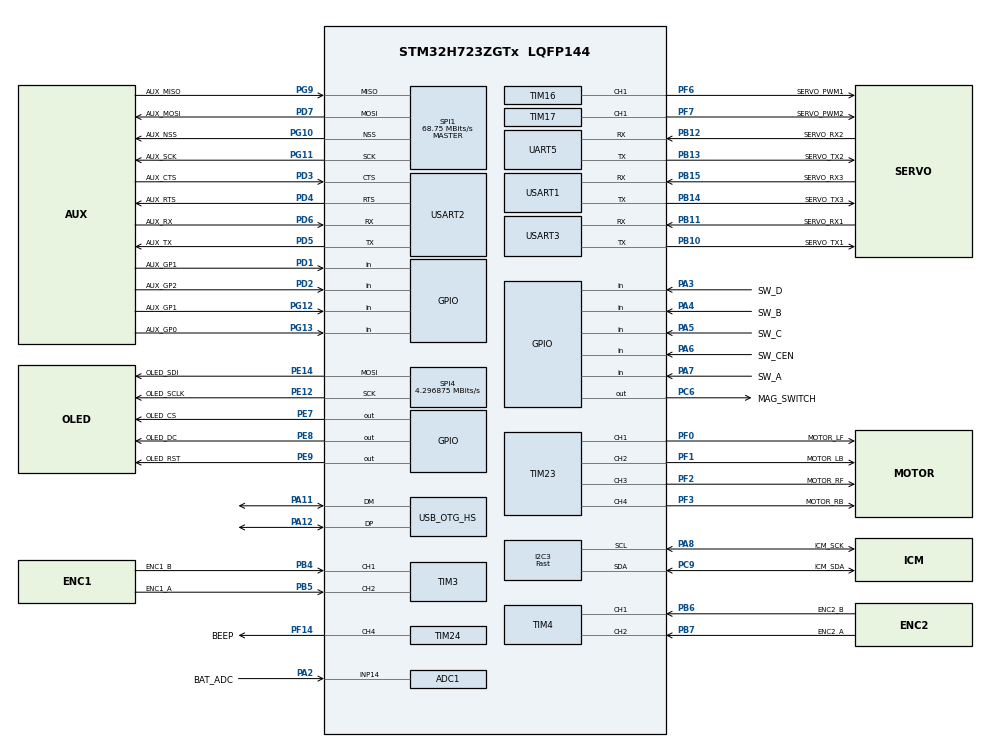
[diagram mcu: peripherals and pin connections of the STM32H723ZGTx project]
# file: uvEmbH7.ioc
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ADC1.Channel-0\#ChannelRegularConversion=ADC_CHANNEL_14
ADC1.ContinuousConvMode=ENABLE
ADC1.NbrOfConversion=1
ADC1.NbrOfConversionFlag=1
ADC1.OffsetNumber-0\#ChannelRegularConversion=ADC_OFFSET_NONE
ADC1.OffsetSignedSaturation-0\#ChannelRegularConversion=DISABLE
ADC1.Overrun=ADC_OVR_DATA_OVERWRITTEN
ADC1.Rank-0\#ChannelRegularConversion=1
ADC1.SamplingTime-0\#ChannelRegularConversion=ADC_SAMPLETIME_1CYCLE_5
ADC1.master=1
ADC3.Channel-0\#ChannelRegularConversion=ADC_CHANNEL_VBAT
ADC3.NbrOfConversionFlag=1
ADC3.OffsetNumber-0\#ChannelRegularConversion=ADC_OFFSET_NONE
ADC3.OffsetSign-0\#ChannelRegularConversion=ADC3_OFFSET_SIGN_NEGATIVE
ADC3.Rank-0\#ChannelRegularConversion=1
ADC3.SamplingTime-0\#ChannelRegularConversion=ADC3_SAMPLETIME_2CYCLES_5
CORTEX_M7.default_mode_Activation=1
FREERTOS.Tasks01=defaultTask,24,128,StartDefaultTask,Default,NULL,Dynamic,NULL,NULL
FREERTOS.configENABLE_FPU=1
FREERTOS.configTOTAL_HEAP_SIZE=32767
FREERTOS.configUSE_NEWLIB_REENTRANT=1
I2C3.Analog_Filter=I2C_ANALOGFILTER_DISABLE
I2C3.I2C_Speed_Mode=I2C_Fast
I2C3.Timing=0x00D056FC
Mcu.Family=STM32H7
Mcu.Name=STM32H723ZGTx
Mcu.Package=LQFP144
NVIC.OTG_HS_IRQn=true\:5\:0\:false\:false\:true\:true\:true\:false\:true
NVIC.PriorityGroup=NVIC_PRIORITYGROUP_4
NVIC.TIM6_DAC_IRQn=true\:15\:0\:false\:false\:true\:false\:false\:true\:true
NVIC.TimeBase=TIM6_DAC_IRQn
NVIC.TimeBaseIP=TIM6
PA11.Mode=Device_Only_FS
PA11.Signal=USB_OTG_HS_DM
PA12.Mode=Device_Only_FS
PA12.Signal=USB_OTG_HS_DP
PA13(JTMS/SWDIO).Mode=Serial_Wire
PA13(JTMS/SWDIO).Signal=DEBUG_JTMS-SWDIO
PA14(JTCK/SWCLK).Mode=Serial_Wire
PA14(JTCK/SWCLK).Signal=DEBUG_JTCK-SWCLK
PA2.GPIO_Label=BAT_ADC
PA2.Signal=ADCx_INP14
PA3.GPIO_Label=SW_D
PA3.GPIO_PuPd=GPIO_PULLUP
PA3.Signal=GPIO_Input
PA4.GPIO_Label=SW_B
PA4.GPIO_PuPd=GPIO_PULLUP
PA4.Signal=GPIO_Input
PA5.GPIO_Label=SW_C
PA5.GPIO_PuPd=GPIO_PULLUP
PA5.Signal=GPIO_Input
PA6.GPIO_Label=SW_CEN
PA6.GPIO_PuPd=GPIO_PULLUP
PA6.Signal=GPIO_Input
PA7.GPIO_Label=SW_A
PA7.GPIO_PuPd=GPIO_PULLUP
PA7.Signal=GPIO_Input
PA8.GPIO_Label=ICM_SCK
PA8.GPIO_Pu=GPIO_PULLUP
PA8.GPIO_Speed=GPIO_SPEED_FREQ_VERY_HIGH
PA8.Mode=I2C
PA8.Signal=I2C3_SCL
PB10.GPIO_Label=SERVO_TX1
PB10.GPIO_Speed=GPIO_SPEED_FREQ_VERY_HIGH
PB10.Mode=Asynchronous
PB10.Signal=USART3_TX
PB11.GPIO_Label=SERVO_RX1
PB11.GPIO_Speed=GPIO_SPEED_FREQ_VERY_HIGH
PB11.Mode=Asynchronous
PB11.Signal=USART3_RX
PB12.GPIO_Label=SERVO_RX2
PB12.GPIO_Speed=GPIO_SPEED_FREQ_VERY_HIGH
PB12.Mode=Asynchronous
PB12.Signal=UART5_RX
PB13.GPIO_Label=SERVO_TX2
PB13.GPIO_Speed=GPIO_SPEED_FREQ_VERY_HIGH
PB13.Mode=Asynchronous
PB13.Signal=UART5_TX
PB14.GPIO_Label=SERVO_TX3
PB14.GPIO_Speed=GPIO_SPEED_FREQ_VERY_HIGH
PB14.Mode=Asynchronous
PB14.Signal=USART1_TX
PB15.GPIO_Label=SERVO_RX3
PB15.GPIO_Speed=GPIO_SPEED_FREQ_VERY_HIGH
PB15.Mode=Asynchronous
PB15.Signal=USART1_RX
PB4(NJTRST).GPIO_Label=ENC1_B
PB4(NJTRST).GPIO_Speed=GPIO_SPEED_FREQ_VERY_HIGH
PB4(NJTRST).Signal=S_TIM3_CH1
PB5.GPIO_Label=ENC1_A
PB5.GPIO_Speed=GPIO_SPEED_FREQ_VERY_HIGH
PB5.Signal=S_TIM3_CH2
PB6.GPIO_Label=ENC2_B
PB6.GPIO_Speed=GPIO_SPEED_FREQ_VERY_HIGH
PB6.Signal=S_TIM4_CH1
PB7.GPIO_Label=ENC2_A
PB7.GPIO_Speed=GPIO_SPEED_FREQ_VERY_HIGH
PB7.Signal=S_TIM4_CH2
PC14-OSC32_IN.Mode=LSE-External-Oscillator
PC14-OSC32_IN.Signal=RCC_OSC32_IN
PC15-OSC32_OUT.Mode=LSE-External-Oscillator
PC15-OSC32_OUT.Signal=RCC_OSC32_OUT
PC6.GPIO_Label=MAG_SWITCH
PC6.GPIO_PuPd=GPIO_PULLDOWN
PC6.GPIO_Speed=GPIO_SPEED_FREQ_VERY_HIGH
PC6.Signal=GPIO_Output
PC9.GPIO_Label=ICM_SDA
PC9.GPIO_Pu=GPIO_PULLUP
PC9.GPIO_Speed=GPIO_SPEED_FREQ_VERY_HIGH
PC9.Mode=I2C
PC9.Signal=I2C3_SDA
PD1.GPIO_Label=AUX_GP1
PD1.GPIO_PuPd=GPIO_PULLUP
PD1.Signal=GPIO_Input
PD2.GPIO_Label=AUX_GP2
PD2.GPIO_PuPd=GPIO_PULLUP
PD2.Signal=GPIO_Input
PD3.GPIO_Label=AUX_CTS
PD3.GPIO_Speed=GPIO_SPEED_FREQ_VERY_HIGH
PD3.Mode=CTS_RTS
PD3.Signal=USART2_CTS
PD4.GPIO_Label=AUX_RTS
PD4.GPIO_Speed=GPIO_SPEED_FREQ_VERY_HIGH
PD4.Mode=CTS_RTS
PD4.Signal=USART2_RTS
PD5.GPIO_Label=AUX_TX
PD5.GPIO_Speed=GPIO_SPEED_FREQ_VERY_HIGH
PD5.Mode=Asynchronous
PD5.Signal=USART2_TX
PD6.GPIO_Label=AUX_RX
PD6.GPIO_Speed=GPIO_SPEED_FREQ_VERY_HIGH
PD6.Mode=Asynchronous
PD6.Signal=USART2_RX
PD7.GPIO_Label=AUX_MOSI
PD7.GPIO_Speed=GPIO_SPEED_FREQ_VERY_HIGH
PD7.Mode=Full_Duplex_Master
PD7.Signal=SPI1_MOSI
PE12.GPIO_Label=OLED_SCLK
PE12.GPIO_Speed=GPIO_SPEED_FREQ_VERY_HIGH
PE12.Mode=TX_Only_Simplex_Unidirect_Master
PE12.Signal=SPI4_SCK
PE14.GPIO_Label=OLED_SDI
PE14.GPIO_Speed=GPIO_SPEED_FREQ_VERY_HIGH
PE14.Mode=TX_Only_Simplex_Unidirect_Master
PE14.Signal=SPI4_MOSI
PE7.GPIO_Label=OLED_CS
PE7.GPIO_PuPd=GPIO_PULLUP
PE7.GPIO_Speed=GPIO_SPEED_FREQ_VERY_HIGH
PE7.PinState=GPIO_PIN_SET
PE7.Signal=GPIO_Output
PE8.GPIO_Label=OLED_DC
PE8.GPIO_PuPd=GPIO_PULLUP
PE8.GPIO_Speed=GPIO_SPEED_FREQ_VERY_HIGH
PE8.PinState=GPIO_PIN_SET
PE8.Signal=GPIO_Output
PE9.GPIO_Label=OLED_RST
PE9.GPIO_PuPd=GPIO_PULLUP
PE9.GPIO_Speed=GPIO_SPEED_FREQ_VERY_HIGH
PE9.PinState=GPIO_PIN_SET
PE9.Signal=GPIO_Output
PF0.GPIO_Label=MOTOR_LF
PF0.GPIO_PuPd=GPIO_PULLDOWN
PF0.GPIO_Speed=GPIO_SPEED_FREQ_VERY_HIGH
PF0.Mode=PWM Generation1 CH1
PF0.Signal=TIM23_CH1
PF1.GPIO_Label=MOTOR_LB
PF1.GPIO_PuPd=GPIO_PULLDOWN
PF1.GPIO_Speed=GPIO_SPEED_FREQ_VERY_HIGH
PF1.Signal=S_TIM23_CH2
PF14.GPIO_Label=BEEP
PF14.GPIO_PuPd=GPIO_NOPULL
PF14.GPIO_Speed=GPIO_SPEED_FREQ_VERY_HIGH
PF14.Signal=S_TIM24_CH4
PF2.GPIO_Label=MOTOR_RF
PF2.GPIO_PuPd=GPIO_PULLDOWN
PF2.GPIO_Speed=GPIO_SPEED_FREQ_VERY_HIGH
PF2.Signal=S_TIM23_CH3
PF3.GPIO_Label=MOTOR_RB
PF3.GPIO_PuPd=GPIO_PULLDOWN
PF3.GPIO_Speed=GPIO_SPEED_FREQ_VERY_HIGH
PF3.Signal=S_TIM23_CH4
PF6.GPIO_Label=SERVO_PWM1
PF6.GPIO_PuPd=GPIO_PULLDOWN
PF6.GPIO_Speed=GPIO_SPEED_FREQ_VERY_HIGH
PF6.Signal=S_TIM16_CH1
PF7.GPIO_Label=SERVO_PWM2
PF7.GPIO_PuPd=GPIO_PULLDOWN
PF7.GPIO_Speed=GPIO_SPEED_FREQ_VERY_HIGH
PF7.Signal=S_TIM17_CH1
PG10.GPIO_Label=AUX_NSS
PG10.GPIO_Speed=GPIO_SPEED_FREQ_VERY_HIGH
PG10.Mode=NSS_Signal_Hard_Output
PG10.Signal=SPI1_NSS
PG11.GPIO_Label=AUX_SCK
PG11.GPIO_Speed=GPIO_SPEED_FREQ_VERY_HIGH
PG11.Mode=Full_Duplex_Master
PG11.Signal=SPI1_SCK
PG12.GPIO_Label=AUX_GP1
PG12.GPIO_PuPd=GPIO_PULLUP
PG12.Signal=GPIO_Input
PG13.GPIO_Label=AUX_GP0
PG13.GPIO_PuPd=GPIO_PULLUP
PG13.Signal=GPIO_Input
PG9.GPIO_Label=AUX_MISO
PG9.GPIO_Speed=GPIO_SPEED_FREQ_VERY_HIGH
PG9.Mode=Full_Duplex_Master
PG9.Signal=SPI1_MISO
PH0-OSC_IN.Mode=HSE-External-Oscillator
PH0-OSC_IN.Signal=RCC_OSC_IN
PH1-OSC_OUT.Mode=HSE-External-Oscillator
PH1-OSC_OUT.Signal=RCC_OSC_OUT
ProjectManager.HeapSize=0x2000
ProjectManager.StackSize=0x4000
ProjectManager.TargetToolchain=STM32CubeIDE
RCC.ADCFreq_Value=96000000
RCC.APB1Freq_Value=137500000
RCC.APB2Freq_Value=137500000
RCC.APB3Freq_Value=137500000
RCC.APB4Freq_Value=137500000
RCC.CortexFreq_Value=550000000
RCC.D1PPRE=RCC_APB3_DIV2
RCC.D2PPRE1=RCC_APB1_DIV2
RCC.D2PPRE2=RCC_APB2_DIV2
RCC.D3PPRE=RCC_APB4_DIV2
RCC.DIVM1=1
RCC.DIVM2=1
RCC.DIVM3=1
RCC.DIVN1=68
RCC.DIVN2=24
RCC.DIVN3=24
RCC.DIVP1=1
RCC.DIVQ1=4
RCC.DIVQ3=4
RCC.HCLKFreq_Value=275000000
RCC.HPRE=RCC_HCLK_DIV2
RCC.HSE_VALUE=8000000
RCC.PLL2FRACN=0
RCC.PLL3FRACN=0
RCC.PLLFRACN=6144
RCC.SYSCLKFreq_VALUE=550000000
RCC.SYSCLKSource=RCC_SYSCLKSOURCE_PLLCLK
RCC.USBCLockSelection=RCC_USBCLKSOURCE_PLL3
RCC.USBFreq_Value=48000000
SH.ADCx_INP14.0=ADC1_INP14,IN14-Single-Ended
SH.S_TIM16_CH1.0=TIM16_CH1,PWM Generation1 CH1
SH.S_TIM17_CH1.0=TIM17_CH1,PWM Generation1 CH1
SH.S_TIM23_CH2.0=TIM23_CH2,PWM Generation2 CH2
SH.S_TIM23_CH3.0=TIM23_CH3,PWM Generation3 CH3
SH.S_TIM23_CH4.0=TIM23_CH4,PWM Generation4 CH4
SH.S_TIM24_CH4.0=TIM24_CH4,PWM Generation4 CH4
SH.S_TIM3_CH1.0=TIM3_CH1,Encoder_Interface
SH.S_TIM3_CH2.0=TIM3_CH2,Encoder_Interface
SH.S_TIM4_CH1.0=TIM4_CH1,Encoder_Interface
SH.S_TIM4_CH2.0=TIM4_CH2,Encoder_Interface
SPI1.CalculateBaudRate=68.75 MBits/s
SPI1.Direction=SPI_DIRECTION_2LINES
SPI1.Mode=SPI_MODE_MASTER
SPI1.VirtualNSS=VM_NSSHARD
SPI1.VirtualType=VM_MASTER
SPI4.BaudRatePrescaler=SPI_BAUDRATEPRESCALER_32
SPI4.CalculateBaudRate=4.296875 MBits/s
SPI4.DataSize=SPI_DATASIZE_8BIT
SPI4.Direction=SPI_DIRECTION_2LINES_TXONLY
SPI4.Mode=SPI_MODE_MASTER
SPI4.VirtualType=VM_MASTER
STMicroelectronics.X-CUBE-MEMS1.11.0.0.SensorsJjSTM32IiMotionFXIiLibraryJjCore=true
TIM16.Channel=TIM_CHANNEL_1
TIM17.Channel=TIM_CHANNEL_1
TIM23.Channel-PWM\ Generation1\ CH1=TIM_CHANNEL_1
TIM23.Channel-PWM\ Generation2\ CH2=TIM_CHANNEL_2
TIM23.Channel-PWM\ Generation3\ CH3=TIM_CHANNEL_3
TIM23.Channel-PWM\ Generation4\ CH4=TIM_CHANNEL_4
TIM23.OCMode_PWM-PWM\ Generation1\ CH1=TIM_OCMODE_PWM2
TIM23.OCMode_PWM-PWM\ Generation2\ CH2=TIM_OCMODE_PWM2
TIM23.OCMode_PWM-PWM\ Generation3\ CH3=TIM_OCMODE_PWM2
TIM23.OCMode_PWM-PWM\ Generation4\ CH4=TIM_OCMODE_PWM2
TIM24.AutoReloadPreload=TIM_AUTORELOAD_PRELOAD_DISABLE
TIM24.Channel-PWM\ Generation4\ CH4=TIM_CHANNEL_4
TIM24.OC4Preload_PWM=DISABLE
TIM24.OCFastMode_PWM-PWM\ Generation4\ CH4=TIM_OCFAST_ENABLE
TIM24.OCMode_PWM-PWM\ Generation4\ CH4=TIM_OCMODE_PWM2
USART1.VirtualMode-Asynchronous=VM_ASYNC
USART2.VirtualMode-Asynchronous=VM_ASYNC
USART3.VirtualMode-Asynchronous=VM_ASYNC
USB_OTG_HS.VirtualMode-Device_Only_FS=Device_Only_FS
VP_ADC3_TempSens_Input.Mode=IN-TempSens
VP_ADC3_Vbat_Input.Mode=IN-Vbat
VP_ADC3_Vref_Input.Mode=IN-Vrefint
VP_CORDIC_VS_CORDIC.Mode=CORDIC_Activate
VP_CRC_VS_CRC.Mode=CRC_Activate
VP_FREERTOS_VS_CMSIS_V2.Mode=CMSIS_V2
VP_MEMORYMAP_VS_MEMORYMAP.Mode=CurAppReg
VP_RNG_VS_RNG.Mode=RNG_Activate
VP_STMicroelectronics.X-CUBE-MEMS1_VS_SensorsJjSTM32IiMotionFXIiLibrary_2.8.0_11.0.0.Mode=SensorsJjSTM32IiMotionFXIiLibrary
VP_SYS_VS_tim6.Mode=TIM6
VP_TIM16_VS_ClockSourceINT.Mode=Enable_Timer
VP_TIM17_VS_ClockSourceINT.Mode=Enable_Timer
VP_TIM23_VS_ClockSourceINT.Mode=Internal
VP_TIM24_VS_ClockSourceINT.Mode=Internal
board=custom

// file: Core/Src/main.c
/* USER CODE BEGIN Header */
/**
  ******************************************************************************
  * @file           : main.c
  * @brief          : Main program body
  ******************************************************************************
  * @attention
  *
  * Copyright (c) 2024 STMicroelectronics.
  * All rights reserved.
  *
  * This software is licensed under terms that can be found in the LICENSE file
  * in the root directory of this software component.
  * If no LICENSE file comes with this software, it is provided AS-IS.
  *
  ******************************************************************************
  */
/* USER CODE END Header */
#include "main.h"
#include "cmsis_os.h"
#include "adc.h"
#include "cordic.h"
#include "crc.h"
#include "i2c.h"
#include "memorymap.h"
#include "rng.h"
#include "spi.h"
#include "tim.h"
#include "usart.h"
#include "usb_otg.h"
#include "gpio.h"

/* USER CODE BEGIN Includes */
#include "apps.h"
/* USER CODE END Includes */

void SystemClock_Config(void);
void PeriphCommonClock_Config(void);
static void MPU_Config(void);
void MX_FREERTOS_Init(void);

int main(void)
{

  /* MPU Configuration--------------------------------------------------------*/
  MPU_Config();

  /* MCU Configuration--------------------------------------------------------*/

  /* Reset of all peripherals, Initializes the Flash interface and the Systick. */
  HAL_Init();

  /* Configure the system clock */
  SystemClock_Config();

  /* Configure the peripherals common clocks */
  PeriphCommonClock_Config();

  /* Initialize all configured peripherals */
  MX_GPIO_Init();
  MX_CORDIC_Init();
  MX_CRC_Init();
  MX_RNG_Init();
  MX_ADC3_Init();
  MX_I2C3_Init();
  MX_SPI4_Init();
  MX_TIM3_Init();
  MX_TIM4_Init();
  MX_TIM16_Init();
  MX_TIM17_Init();
  MX_TIM23_Init();
  MX_UART5_Init();
  MX_USART1_UART_Init();
  MX_USART3_UART_Init();
  MX_ADC1_Init();
  MX_SPI1_Init();
  MX_USART2_UART_Init();
  MX_TIM24_Init();
  MX_USB_OTG_HS_PCD_Init();

  /* Init scheduler */
  osKernelInitialize();

  /* Call init function for freertos objects (in cmsis_os2.c) */
  MX_FREERTOS_Init();

  /* Start scheduler */
  osKernelStart();

  /* We should never get here as control is now taken by the scheduler */

  /* Infinite loop */
  /* USER CODE BEGIN WHILE */
  // board_init();
  while (1)
  {
    /* USER CODE END WHILE */

    /* USER CODE BEGIN 3 */
//	if (HAL_GPIO_ReadPin(SW_A_GPIO_Port, SW_A_Pin) == 0)
//	{
//		_set_pwm_freq(NOTE_C6);
//		emag_enable();
//	}
//	else
//	{
//		_set_pwm_freq(0);
//		emag_disable();
//	}
//	HAL_Delay(200);
  }
  /* USER CODE END 3 */
}

void SystemClock_Config(void)
{
  RCC_OscInitTypeDef RCC_OscInitStruct = {0};
  RCC_ClkInitTypeDef RCC_ClkInitStruct = {0};

  /** Supply configuration update enable
  */
  HAL_PWREx_ConfigSupply(PWR_LDO_SUPPLY);

  /** Configure the main internal regulator output voltage
  */
  __HAL_PWR_VOLTAGESCALING_CONFIG(PWR_REGULATOR_VOLTAGE_SCALE0);

  while(!__HAL_PWR_GET_FLAG(PWR_FLAG_VOSRDY)) {}

  /** Initializes the RCC Oscillators according to the specified parameters
  * in the RCC_OscInitTypeDef structure.
  */
  RCC_OscInitStruct.OscillatorType = RCC_OSCILLATORTYPE_HSI48|RCC_OSCILLATORTYPE_HSE;
  RCC_OscInitStruct.HSEState = RCC_HSE_ON;
  RCC_OscInitStruct.HSI48State = RCC_HSI48_ON;
  RCC_OscInitStruct.PLL.PLLState = RCC_PLL_ON;
  RCC_OscInitStruct.PLL.PLLSource = RCC_PLLSOURCE_HSE;
  RCC_OscInitStruct.PLL.PLLM = 1;
  RCC_OscInitStruct.PLL.PLLN = 68;
  RCC_OscInitStruct.PLL.PLLP = 1;
  RCC_OscInitStruct.PLL.PLLQ = 4;
  RCC_OscInitStruct.PLL.PLLR = 2;
  RCC_OscInitStruct.PLL.PLLRGE = RCC_PLL1VCIRANGE_3;
  RCC_OscInitStruct.PLL.PLLVCOSEL = RCC_PLL1VCOWIDE;
  RCC_OscInitStruct.PLL.PLLFRACN = 6144;
  if (HAL_RCC_OscConfig(&RCC_OscInitStruct) != HAL_OK)
  {
    Error_Handler();
  }

  /** Initializes the CPU, AHB and APB buses clocks
  */
  RCC_ClkInitStruct.ClockType = RCC_CLOCKTYPE_HCLK|RCC_CLOCKTYPE_SYSCLK
                              |RCC_CLOCKTYPE_PCLK1|RCC_CLOCKTYPE_PCLK2
                              |RCC_CLOCKTYPE_D3PCLK1|RCC_CLOCKTYPE_D1PCLK1;
  RCC_ClkInitStruct.SYSCLKSource = RCC_SYSCLKSOURCE_PLLCLK;
  RCC_ClkInitStruct.SYSCLKDivider = RCC_SYSCLK_DIV1;
  RCC_ClkInitStruct.AHBCLKDivider = RCC_HCLK_DIV2;
  RCC_ClkInitStruct.APB3CLKDivider = RCC_APB3_DIV2;
  RCC_ClkInitStruct.APB1CLKDivider = RCC_APB1_DIV2;
  RCC_ClkInitStruct.APB2CLKDivider = RCC_APB2_DIV2;
  RCC_ClkInitStruct.APB4CLKDivider = RCC_APB4_DIV2;

  if (HAL_RCC_ClockConfig(&RCC_ClkInitStruct, FLASH_LATENCY_3) != HAL_OK)
  {
    Error_Handler();
  }
}

void PeriphCommonClock_Config(void)
{
  RCC_PeriphCLKInitTypeDef PeriphClkInitStruct = {0};

  /** Initializes the peripherals clock
  */
  PeriphClkInitStruct.PeriphClockSelection = RCC_PERIPHCLK_ADC;
  PeriphClkInitStruct.PLL2.PLL2M = 1;
  PeriphClkInitStruct.PLL2.PLL2N = 24;
  PeriphClkInitStruct.PLL2.PLL2P = 2;
  PeriphClkInitStruct.PLL2.PLL2Q = 2;
  PeriphClkInitStruct.PLL2.PLL2R = 2;
  PeriphClkInitStruct.PLL2.PLL2RGE = RCC_PLL2VCIRANGE_3;
  PeriphClkInitStruct.PLL2.PLL2VCOSEL = RCC_PLL2VCOWIDE;
  PeriphClkInitStruct.PLL2.PLL2FRACN = 0;
  PeriphClkInitStruct.AdcClockSelection = RCC_ADCCLKSOURCE_PLL2;
  if (HAL_RCCEx_PeriphCLKConfig(&PeriphClkInitStruct) != HAL_OK)
  {
    Error_Handler();
  }
}

 /* MPU Configuration */

void MPU_Config(void)
{
  MPU_Region_InitTypeDef MPU_InitStruct = {0};

  /* Disables the MPU */
  HAL_MPU_Disable();

  /** Initializes and configures the Region and the memory to be protected
  */
  MPU_InitStruct.Enable = MPU_REGION_ENABLE;
  MPU_InitStruct.Number = MPU_REGION_NUMBER0;
  MPU_InitStruct.BaseAddress = 0x0;
  MPU_InitStruct.Size = MPU_REGION_SIZE_4GB;
  MPU_InitStruct.SubRegionDisable = 0x87;
  MPU_InitStruct.TypeExtField = MPU_TEX_LEVEL0;
  MPU_InitStruct.AccessPermission = MPU_REGION_NO_ACCESS;
  MPU_InitStruct.DisableExec = MPU_INSTRUCTION_ACCESS_DISABLE;
  MPU_InitStruct.IsShareable = MPU_ACCESS_SHAREABLE;
  MPU_InitStruct.IsCacheable = MPU_ACCESS_NOT_CACHEABLE;
  MPU_InitStruct.IsBufferable = MPU_ACCESS_NOT_BUFFERABLE;

  HAL_MPU_ConfigRegion(&MPU_InitStruct);
  /* Enables the MPU */
  HAL_MPU_Enable(MPU_PRIVILEGED_DEFAULT);

}

void HAL_TIM_PeriodElapsedCallback(TIM_HandleTypeDef *htim)
{
  if (htim->Instance == TIM6) {
    HAL_IncTick();
  }
}

void Error_Handler(void)
{
  __disable_irq();
  while (1)
  {
  }
}

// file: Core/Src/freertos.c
/* USER CODE BEGIN Header */
/**
  ******************************************************************************
  * File Name          : freertos.c
  * Description        : Code for freertos applications
  ******************************************************************************
  * @attention
  *
  * Copyright (c) 2024 STMicroelectronics.
  * All rights reserved.
  *
  * This software is licensed under terms that can be found in the LICENSE file
  * in the root directory of this software component.
  * If no LICENSE file comes with this software, it is provided AS-IS.
  *
  ******************************************************************************
  */
/* USER CODE END Header */

#include "FreeRTOS.h"
#include "task.h"
#include "main.h"
#include "cmsis_os.h"

/* USER CODE BEGIN Includes */
#include "apps.h"
/* USER CODE END Includes */

/* Definitions for defaultTask */
osThreadId_t defaultTaskHandle;
const osThreadAttr_t defaultTask_attributes = {
  .name = "defaultTask",
  .stack_size = 128 * 4,
  .priority = (osPriority_t) osPriorityNormal,
};

void StartDefaultTask(void *argument);

void MX_FREERTOS_Init(void); /* (MISRA C 2004 rule 8.1) */

void MX_FREERTOS_Init(void) {
  /* USER CODE BEGIN Init */
  board_init();
  apps_init();
  /* USER CODE END Init */

  /* Create the thread(s) */
  /* creation of defaultTask */
  defaultTaskHandle = osThreadNew(StartDefaultTask, NULL, &defaultTask_attributes);

  /* USER CODE BEGIN RTOS_THREADS */
  /* add threads, ... */
  apps_start();
  /* USER CODE END RTOS_THREADS */

}

void StartDefaultTask(void *argument)
{
  /* USER CODE BEGIN StartDefaultTask */
  // buzzer_init();
  /* Infinite loop */
  for(;;)
  {
//	if (osMutexAcquire(mtx_buzzerToneHandle, 0x0) == osOK)
//	{
//		buzzer_update();
//		osMutexRelease(mtx_buzzerToneHandle);
//	}
    osDelay(1000);
  }
  /* USER CODE END StartDefaultTask */
}
